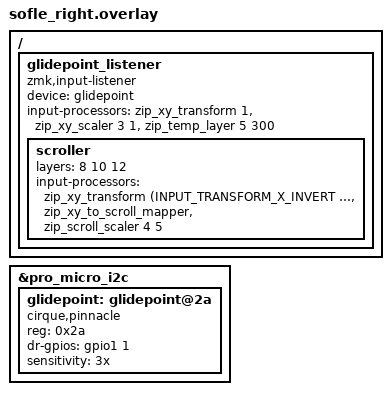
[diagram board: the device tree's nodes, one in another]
#include <dt-bindings/zmk/input_transform.h>
#include <input/processors.dtsi>


/ {
    /* Dieser Listener sorgt dafür, dass die Daten vom Glidepoint 
       tatsächlich in Mausbewegungen umgewandelt werden */
    glidepoint_listener: glidepoint_listener {
        compatible = "zmk,input-listener";
        device = <&glidepoint>;

        input-processors = 
            <&zip_xy_transform 1>,
            <&zip_xy_scaler 3 1>,
            <&zip_temp_layer 5 300>;    // mouse layer 5 and timeout setting
        
        scroller {
            layers = <8 10 12>;                      // Scroll-layer und nav und number layer
            input-processors = 
                <&zip_xy_transform (INPUT_TRANSFORM_X_INVERT | 1)>,
                <&zip_xy_to_scroll_mapper>,    // X/Y zu Scroll umwandeln
                <&zip_scroll_scaler 4 5>;      // Scroll-Geschwindigkeit drosseln
        };
    };
};

&pro_micro_i2c {
    status = "okay";
	// clock-frequency = <400000>;		// zum testen auf I2C High Modus

    glidepoint: glidepoint@2a {
        compatible = "cirque,pinnacle";
        reg = <0x2a>;
        status = "okay";
        dr-gpios = <&gpio1 1 (GPIO_ACTIVE_HIGH)>; 
        sensitivity = "3x";

        // Optional: turning this on enables very aggressive power saving, after 5 seconds with no touches
        // the trackpad will go to sleep.  It wakes up on touch, but there is a ~300ms delay.  Most users will find
        // the standard behavior of 'put to sleep when zmk enters idle state (30 seconds without a keypress) feels better.
	    // sleep;
    };
};
